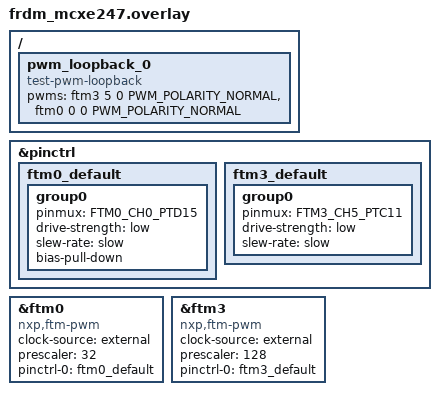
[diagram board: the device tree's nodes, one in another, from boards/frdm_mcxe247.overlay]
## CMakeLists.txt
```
# Copyright 2026 NXP
# SPDX-License-Identifier: Apache-2.0

cmake_minimum_required(VERSION 3.28.0)

# Same test-pwm-loopback binding and wiring as the pwm_loopback test
list(APPEND DTS_ROOT ${CMAKE_CURRENT_SOURCE_DIR}/../pwm_loopback)

find_package(Zephyr REQUIRED HINTS $ENV{ZEPHYR_BASE})
project(pwm_pm)

target_sources(app PRIVATE src/main.c)
target_sources_ifdef(CONFIG_PM_POLICY_DEVICE_CONSTRAINTS app PRIVATE src/policy.c)

# PM_DEVICE_SYSTEM_MANAGED defaults on with PM_DEVICE alone; the sweep only
# exists with system PM.
if(CONFIG_PM AND CONFIG_PM_DEVICE_SYSTEM_MANAGED)
  target_sources(app PRIVATE src/sysmanaged.c)
endif()
```

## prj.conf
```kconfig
CONFIG_ZTEST=y

CONFIG_PWM=y
CONFIG_PWM_CAPTURE=y

CONFIG_PM_DEVICE=y
```

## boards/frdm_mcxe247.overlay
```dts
/*
 * Copyright 2026 NXP
 *
 * SPDX-License-Identifier: Apache-2.0
 */

#include <zephyr/dt-bindings/pwm/pwm.h>

&pinctrl {
	ftm0_default: ftm0_default {
		group0 {
			pinmux = <FTM0_CH0_PTD15>;
			drive-strength = "low";
			slew-rate = "slow";
			/* A suspended FTM leaves its output floating; keep the
			 * line low so a capture on it times out instead of
			 * catching noise.
			 */
			bias-pull-down;
		};
	};

	ftm3_default: ftm3_default {
		group0 {
			pinmux = <FTM3_CH5_PTC11>;
			drive-strength = "low";
			slew-rate = "slow";
		};
	};
};

/* To test this sample, connect
 * PTC11(J1-12) ---> PTD15(J1-14)
 */

/ {
	pwm_loopback_0 {
		compatible = "test-pwm-loopback";
		pwms = <&ftm3 5 0 PWM_POLARITY_NORMAL>, /* PTC11 J1 pin 12 out */
		       <&ftm0 0 0 PWM_POLARITY_NORMAL>; /* PTD15 J1 pin 14 in */
	};
};

&ftm0 {
	compatible = "nxp,ftm-pwm";
	clock-source = "external";
	prescaler = <32>;
	#pwm-cells = <3>;
	pinctrl-0 = <&ftm0_default>;
	pinctrl-names = "default";
	status = "okay";
};

&ftm3 {
	compatible = "nxp,ftm-pwm";
	clock-source = "external";
	prescaler = <128>;
	#pwm-cells = <3>;
	pinctrl-0 = <&ftm3_default>;
	pinctrl-names = "default";
	status = "okay";
};
```

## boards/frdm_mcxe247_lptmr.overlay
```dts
/*
 * Copyright 2026 NXP
 *
 * SPDX-License-Identifier: Apache-2.0
 */

/*
 * With CONFIG_PM=y the SoC enters STOP whenever no lock holds it back, and
 * SysTick does not run there. MCXE24x leaves lptmr0 disabled and not marked
 * as a wake-up source, so enable it as the system timer companion or nothing
 * ends the sleep.
 */
&lptmr0 {
	wakeup-source;
	status = "okay";
};

/ {
	chosen {
		zephyr,system-timer-companion = &lptmr0;
	};
};
```

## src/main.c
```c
/*
 * Copyright 2026 NXP
 *
 * SPDX-License-Identifier: Apache-2.0
 */

#include <zephyr/kernel.h>
#include <zephyr/drivers/pwm.h>
#include <zephyr/pm/device.h>
#include <zephyr/sys/atomic.h>
#include <zephyr/ztest.h>

#include "pwm_pm.h"

/* Ten periods of the 10 ms test waveform */
#define CAPTURE_TIMEOUT K_MSEC(100)
/* Two periods, for a new or replayed setup to reach the pin */
#define SETTLE_TIME K_MSEC(20)

#define REPEAT_COUNT 20

const struct pwm_dt_spec pwm_pm_out = PWM_DT_SPEC_GET_BY_IDX(PWM_PM_NODE, 0);
const struct pwm_dt_spec pwm_pm_in = PWM_DT_SPEC_GET_BY_IDX(PWM_PM_NODE, 1);

static atomic_t capture_count;

static int capture_one(pwm_flags_t type, uint32_t *period, uint32_t *pulse)
{
	return pwm_capture_cycles(pwm_pm_in.dev, pwm_pm_in.channel, pwm_pm_in.flags | type,
				  period, pulse, CAPTURE_TIMEOUT);
}

void pwm_pm_start_output(void)
{
	uint64_t cycles_per_sec;
	uint32_t period;
	int err;

	err = pwm_get_cycles_per_sec(pwm_pm_out.dev, pwm_pm_out.channel, &cycles_per_sec);
	zassert_ok(err, "failed to get the output clock rate (err %d)", err);

	period = cycles_per_sec / 100U;
	err = pwm_set_cycles(pwm_pm_out.dev, pwm_pm_out.channel, period, period / 4U,
			     pwm_pm_out.flags);
	zassert_ok(err, "failed to set pwm output (err %d)", err);

	k_sleep(SETTLE_TIME);
}

void pwm_pm_capture(struct pwm_pm_reading *reading)
{
	uint32_t period;
	uint32_t pulse;
	int err;

	*reading = (struct pwm_pm_reading){0};

	err = capture_one(PWM_CAPTURE_TYPE_PERIOD, &period, &pulse);
	if (err == 0) {
		reading->period = period;
	} else {
		zassert_equal(err, -ENOTSUP, "no period on the line (err %d)", err);
	}

	err = capture_one(PWM_CAPTURE_TYPE_PULSE, &period, &pulse);
	if (err == 0) {
		reading->pulse = pulse;
	} else {
		zassert_equal(err, -ENOTSUP, "no pulse on the line (err %d)", err);
	}

	if (reading->period == 0U && reading->pulse == 0U) {
		TC_PRINT("capture not supported\n");
		ztest_test_skip();
	}
}

void pwm_pm_action(const struct device *dev, enum pm_device_action action)
{
	static const enum pm_device_state target[] = {
		[PM_DEVICE_ACTION_SUSPEND] = PM_DEVICE_STATE_SUSPENDED,
		[PM_DEVICE_ACTION_RESUME] = PM_DEVICE_STATE_ACTIVE,
		[PM_DEVICE_ACTION_TURN_OFF] = PM_DEVICE_STATE_OFF,
		[PM_DEVICE_ACTION_TURN_ON] = PM_DEVICE_STATE_SUSPENDED,
	};
	enum pm_device_state state;
	int err;

	err = pm_device_action_run(dev, action);
	if (action == PM_DEVICE_ACTION_TURN_OFF || action == PM_DEVICE_ACTION_TURN_ON) {
		/* The PM core moves the state on even when the driver does not
		 * handle these, since they report a power change that happened
		 * anyway.
		 */
		zassert_true(err == 0 || err == -ENOTSUP, "%s: action %d failed (err %d)",
			     dev->name, action, err);
	} else {
		zassert_ok(err, "%s: action %d failed (err %d)", dev->name, action, err);
	}

	err = pm_device_state_get(dev, &state);
	zassert_ok(err, "%s: no pm state (err %d)", dev->name, err);
	zassert_equal(state, target[action], "%s is %s after action %d", dev->name,
		      pm_device_state_str(state), action);
}

static void expect_no_output(void)
{
	uint32_t period;
	uint32_t pulse;
	int err;

	err = capture_one(PWM_CAPTURE_TYPE_PERIOD, &period, &pulse);
	if (err == -ENOTSUP) {
		err = capture_one(PWM_CAPTURE_TYPE_PULSE, &period, &pulse);
	}

	zassert_equal(err, -EAGAIN, "output still running while suspended (err %d)", err);
}

static void expect_same(const struct pwm_pm_reading *ref, const struct pwm_pm_reading *now)
{
	zassert_within(now->period, ref->period, MAX(ref->period / 100U, 1U),
		       "period %u, was %u before the transition", now->period, ref->period);
	zassert_within(now->pulse, ref->pulse, MAX(ref->pulse / 100U, 1U),
		       "pulse %u, was %u before the transition", now->pulse, ref->pulse);
}

/*
 * None of the tests below calls pwm_set again after the transition: the
 * driver has to bring back the waveform it was asked for.
 */
ZTEST(pwm_pm, test_suspend_stops_and_resume_restores)
{
	struct pwm_pm_reading ref;
	struct pwm_pm_reading now;

	pwm_pm_start_output();
	pwm_pm_capture(&ref);

	pwm_pm_action(pwm_pm_out.dev, PM_DEVICE_ACTION_SUSPEND);
	expect_no_output();

	pwm_pm_action(pwm_pm_out.dev, PM_DEVICE_ACTION_RESUME);
	k_sleep(SETTLE_TIME);

	pwm_pm_capture(&now);
	expect_same(&ref, &now);
}

ZTEST(pwm_pm, test_power_cycle_restores)
{
	struct pwm_pm_reading ref;
	struct pwm_pm_reading now;

	pwm_pm_start_output();
	pwm_pm_capture(&ref);

	pwm_pm_action(pwm_pm_out.dev, PM_DEVICE_ACTION_SUSPEND);
	pwm_pm_action(pwm_pm_out.dev, PM_DEVICE_ACTION_TURN_OFF);
	pwm_pm_action(pwm_pm_out.dev, PM_DEVICE_ACTION_TURN_ON);
	pwm_pm_action(pwm_pm_out.dev, PM_DEVICE_ACTION_RESUME);
	k_sleep(SETTLE_TIME);

	pwm_pm_capture(&now);
	expect_same(&ref, &now);
}

ZTEST(pwm_pm, test_repeated_suspend_resume)
{
	struct pwm_pm_reading ref;
	struct pwm_pm_reading now;

	pwm_pm_start_output();
	pwm_pm_capture(&ref);

	for (int i = 0; i < REPEAT_COUNT; i++) {
		pwm_pm_action(pwm_pm_out.dev, PM_DEVICE_ACTION_SUSPEND);
		pwm_pm_action(pwm_pm_out.dev, PM_DEVICE_ACTION_RESUME);
	}
	k_sleep(SETTLE_TIME);

	pwm_pm_capture(&now);
	expect_same(&ref, &now);
}

static void count_capture(const struct device *dev, uint32_t channel, uint32_t period_cycles,
			  uint32_t pulse_cycles, int status, void *user_data)
{
	ARG_UNUSED(dev);
	ARG_UNUSED(channel);
	ARG_UNUSED(period_cycles);
	ARG_UNUSED(pulse_cycles);
	ARG_UNUSED(status);
	ARG_UNUSED(user_data);

	atomic_inc(&capture_count);
}

/*
 * A capture does not survive a suspend: the consumer arms it again. What this
 * checks is that the old one is really gone, rather than left armed in
 * hardware to fire into a callback nobody expects, and that a new one works.
 */
ZTEST(pwm_pm, test_capture_device_suspend)
{
	struct pwm_pm_reading ref;
	struct pwm_pm_reading now;
	enum pm_device_state state;
	pwm_flags_t type;
	atomic_val_t seen;
	int err;

	if (pm_device_state_get(pwm_pm_in.dev, &state) == -ENOSYS) {
		TC_PRINT("%s has no device PM\n", pwm_pm_in.dev->name);
		ztest_test_skip();
	}

	if (pwm_pm_in.dev == pwm_pm_out.dev) {
		TC_PRINT("suspending the capture device would stop the output too\n");
		ztest_test_skip();
	}

	pwm_pm_start_output();
	pwm_pm_capture(&ref);

	type = ref.period != 0U ? PWM_CAPTURE_TYPE_PERIOD : PWM_CAPTURE_TYPE_PULSE;
	atomic_clear(&capture_count);

	err = pwm_configure_capture(pwm_pm_in.dev, pwm_pm_in.channel,
				    pwm_pm_in.flags | PWM_CAPTURE_MODE_CONTINUOUS | type,
				    count_capture, NULL);
	zassert_ok(err, "failed to configure pwm capture (err %d)", err);

	err = pwm_enable_capture(pwm_pm_in.dev, pwm_pm_in.channel);
	zassert_ok(err, "failed to enable pwm capture (err %d)", err);

	k_sleep(K_MSEC(50));
	zassert_true(atomic_get(&capture_count) > 0, "continuous capture saw nothing");

	pwm_pm_action(pwm_pm_in.dev, PM_DEVICE_ACTION_SUSPEND);
	pwm_pm_action(pwm_pm_in.dev, PM_DEVICE_ACTION_RESUME);

	seen = atomic_get(&capture_count);
	k_sleep(K_MSEC(50));
	zassert_equal(atomic_get(&capture_count), seen, "capture still running after a suspend");

	pwm_pm_capture(&now);
	expect_same(&ref, &now);
}

bool pwm_pm_supported(const void *global_state)
{
	enum pm_device_state state;

	ARG_UNUSED(global_state);

	if (!pwm_is_ready_dt(&pwm_pm_out) || !pwm_is_ready_dt(&pwm_pm_in)) {
		TC_PRINT("pwm loopback devices are not ready\n");
		return false;
	}

	if (pm_device_state_get(pwm_pm_out.dev, &state) == -ENOSYS) {
		TC_PRINT("%s has no device PM\n", pwm_pm_out.dev->name);
		return false;
	}

	return true;
}

static void resume_if_needed(const struct device *dev)
{
	enum pm_device_state state;

	if (pm_device_state_get(dev, &state) != 0) {
		return;
	}

	if (state == PM_DEVICE_STATE_OFF) {
		(void)pm_device_action_run(dev, PM_DEVICE_ACTION_TURN_ON);
		state = PM_DEVICE_STATE_SUSPENDED;
	}

	if (state == PM_DEVICE_STATE_SUSPENDED) {
		(void)pm_device_action_run(dev, PM_DEVICE_ACTION_RESUME);
	}
}

void pwm_pm_after(void *fixture)
{
	ARG_UNUSED(fixture);

	/* Resume first: a suspended device may not take register access. */
	resume_if_needed(pwm_pm_out.dev);
	resume_if_needed(pwm_pm_in.dev);

	(void)pwm_disable_capture(pwm_pm_in.dev, pwm_pm_in.channel);
}

ZTEST_SUITE(pwm_pm, pwm_pm_supported, NULL, NULL, pwm_pm_after, NULL);
```

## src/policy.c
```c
/*
 * Copyright 2026 NXP
 *
 * SPDX-License-Identifier: Apache-2.0
 */

#include <zephyr/kernel.h>
#include <zephyr/drivers/pwm.h>
#include <zephyr/pm/device.h>
#include <zephyr/pm/policy.h>
#include <zephyr/pm/state.h>
#include <zephyr/ztest.h>

#include "pwm_pm.h"

#if HAS_DISABLING_STATES(PWM_PM_OUT_CTLR)
static const struct pm_state_constraint out_states[] = DISABLING_STATES(PWM_PM_OUT_CTLR);
#endif

#if HAS_DISABLING_STATES(PWM_PM_IN_CTLR)
static const struct pm_state_constraint in_states[] = DISABLING_STATES(PWM_PM_IN_CTLR);
#endif

static __maybe_unused void expect_locked(const struct pm_state_constraint *states,
					 size_t count, bool locked, const char *when)
{
	for (size_t i = 0; i < count; i++) {
		zassert_equal(pm_policy_state_lock_is_active(states[i].state,
							     states[i].substate_id),
			      locked, "state %d/%u %s %s", states[i].state,
			      states[i].substate_id, locked ? "not locked" : "still locked", when);
	}
}

static __maybe_unused void dummy_capture(const struct device *dev, uint32_t channel,
					 uint32_t period_cycles, uint32_t pulse_cycles,
					 int status, void *user_data)
{
	ARG_UNUSED(dev);
	ARG_UNUSED(channel);
	ARG_UNUSED(period_cycles);
	ARG_UNUSED(pulse_cycles);
	ARG_UNUSED(status);
	ARG_UNUSED(user_data);
}

ZTEST(pwm_pm_policy, test_output_holds_power_lock)
{
#if HAS_DISABLING_STATES(PWM_PM_OUT_CTLR)
	pwm_pm_start_output();
	expect_locked(out_states, ARRAY_SIZE(out_states), true, "while driving");

	pwm_pm_action(pwm_pm_out.dev, PM_DEVICE_ACTION_SUSPEND);
	expect_locked(out_states, ARRAY_SIZE(out_states), false, "after suspend");

	/* The replay on resume drives the output again, so the lock comes back. */
	pwm_pm_action(pwm_pm_out.dev, PM_DEVICE_ACTION_RESUME);
	expect_locked(out_states, ARRAY_SIZE(out_states), true, "after resume");
#else
	TC_PRINT("%s declares no disabling power states\n", pwm_pm_out.dev->name);
	ztest_test_skip();
#endif
}

ZTEST(pwm_pm_policy, test_capture_holds_power_lock)
{
#if HAS_DISABLING_STATES(PWM_PM_IN_CTLR)
	pwm_flags_t flags = pwm_pm_in.flags | PWM_CAPTURE_MODE_CONTINUOUS;
	int err;

	/*
	 * Both ends may lock the same states. Suspend the output so that what
	 * is left to hold them is the capture alone.
	 */
	pwm_pm_start_output();
	pwm_pm_action(pwm_pm_out.dev, PM_DEVICE_ACTION_SUSPEND);
	expect_locked(in_states, ARRAY_SIZE(in_states), false, "with nothing running");

	err = pwm_configure_capture(pwm_pm_in.dev, pwm_pm_in.channel,
				    flags | PWM_CAPTURE_TYPE_PERIOD, dummy_capture, NULL);
	if (err == -ENOTSUP) {
		err = pwm_configure_capture(pwm_pm_in.dev, pwm_pm_in.channel,
					    flags | PWM_CAPTURE_TYPE_PULSE, dummy_capture, NULL);
	}
	zassert_ok(err, "failed to configure pwm capture (err %d)", err);

	err = pwm_enable_capture(pwm_pm_in.dev, pwm_pm_in.channel);
	zassert_ok(err, "failed to enable pwm capture (err %d)", err);
	expect_locked(in_states, ARRAY_SIZE(in_states), true, "while capturing");

	err = pwm_disable_capture(pwm_pm_in.dev, pwm_pm_in.channel);
	zassert_ok(err, "failed to disable pwm capture (err %d)", err);
	expect_locked(in_states, ARRAY_SIZE(in_states), false, "after the capture ended");
#else
	TC_PRINT("%s declares no disabling power states\n", pwm_pm_in.dev->name);
	ztest_test_skip();
#endif
}

ZTEST_SUITE(pwm_pm_policy, pwm_pm_supported, NULL, NULL, pwm_pm_after, NULL);
```

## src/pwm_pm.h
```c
/*
 * Copyright 2026 NXP
 *
 * SPDX-License-Identifier: Apache-2.0
 */

#ifndef __TEST_PWM_PM_H__
#define __TEST_PWM_PM_H__

#include <zephyr/kernel.h>
#include <zephyr/drivers/pwm.h>
#include <zephyr/pm/device.h>
#include <zephyr/pm/state.h>
#include <zephyr/ztest.h>

#define PWM_PM_NODE DT_INST(0, test_pwm_loopback)

/* pwms[0] generates the waveform, pwms[1] captures it */
#define PWM_PM_OUT_CTLR DT_PWMS_CTLR_BY_IDX(PWM_PM_NODE, 0)
#define PWM_PM_IN_CTLR  DT_PWMS_CTLR_BY_IDX(PWM_PM_NODE, 1)

/*
 * The states a node lists in zephyr,disabling-power-states are the ones that
 * stop it, and so the ones its driver locks while it is in use.
 */
#define DISABLING_STATE(idx, node_id)                                                    \
	PM_STATE_CONSTRAINT_INIT(DT_PHANDLE_BY_IDX(node_id, zephyr_disabling_power_states, idx))

#define DISABLING_STATES(node_id)                                                        \
	{LISTIFY(DT_PROP_LEN_OR(node_id, zephyr_disabling_power_states, 0), DISABLING_STATE, \
		 (,), node_id)}

#define HAS_DISABLING_STATES(node_id) DT_NODE_HAS_PROP(node_id, zephyr_disabling_power_states)

/* What the capture side read off the line. A field the capture device cannot
 * measure stays at zero and is not compared.
 */
struct pwm_pm_reading {
	uint32_t period;
	uint32_t pulse;
};

extern const struct pwm_dt_spec pwm_pm_out;
extern const struct pwm_dt_spec pwm_pm_in;

/* Start a 10 ms, 25% waveform on the output. */
void pwm_pm_start_output(void);

/* Capture period and pulse; fails the test if the capture side sees nothing. */
void pwm_pm_capture(struct pwm_pm_reading *reading);

/* Run a PM action and check the state it should leave the device in. */
void pwm_pm_action(const struct device *dev, enum pm_device_action action);

/* Suite predicate: both devices ready and the output one has device PM. */
bool pwm_pm_supported(const void *global_state);

/* Suite after hook: bring both devices back to ACTIVE, capture disabled. */
void pwm_pm_after(void *fixture);

#endif /* __TEST_PWM_PM_H__ */
```

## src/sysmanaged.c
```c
/*
 * Copyright 2026 NXP
 *
 * SPDX-License-Identifier: Apache-2.0
 */

#include <zephyr/kernel.h>
#include <zephyr/drivers/pwm.h>
#include <zephyr/pm/device.h>
#include <zephyr/pm/pm.h>
#include <zephyr/sys/atomic.h>
#include <zephyr/ztest.h>

#include "pwm_pm.h"

/* Long enough for the idle thread to pick a power state many times over */
#define IDLE_TIME K_SECONDS(1)

#if HAS_DISABLING_STATES(PWM_PM_OUT_CTLR)
static const struct pm_state_constraint out_states[] = DISABLING_STATES(PWM_PM_OUT_CTLR);

static atomic_t entries;
static atomic_t stopping_entries;
static atomic_t stopping_state;
static atomic_t stopping_substate;

static bool stops_output(enum pm_state state, uint8_t substate_id)
{
	for (size_t i = 0; i < ARRAY_SIZE(out_states); i++) {
		if (out_states[i].state == state && out_states[i].substate_id == substate_id) {
			return true;
		}
	}

	return false;
}

static void state_entry(enum pm_state state, uint8_t substate_id)
{
	atomic_inc(&entries);

	if (stops_output(state, substate_id)) {
		atomic_set(&stopping_state, state);
		atomic_set(&stopping_substate, substate_id);
		atomic_inc(&stopping_entries);
	}
}

static struct pm_notifier notifier = {
	.substate_entry = state_entry,
	.report_substate = true,
};
#endif /* HAS_DISABLING_STATES(PWM_PM_OUT_CTLR) */

/*
 * The system-managed sweep suspends every device that is not busy before a
 * state deeper than runtime-idle, and pays no attention to policy locks. A
 * driving output stays up only because its lock keeps the states that stop it
 * from being picked at all, so that is what this checks: with the output
 * running, the SoC idles, but never into a state the output node lists in
 * zephyr,disabling-power-states. States it does not list are allowed.
 *
 * A capture taken after waking cannot tell: the sweep resumes the device on
 * the way out, the driver replays the waveform, and the gap is gone.
 */
ZTEST(pwm_pm_sysmanaged, test_output_survives_idle)
{
#if HAS_DISABLING_STATES(PWM_PM_OUT_CTLR)
	struct pwm_pm_reading ref;
	struct pwm_pm_reading now;
	enum pm_device_state state;
	int err;

	pwm_pm_start_output();
	pwm_pm_capture(&ref);

	atomic_clear(&entries);
	atomic_clear(&stopping_entries);

	pm_notifier_register(&notifier);
	k_sleep(IDLE_TIME);
	err = pm_notifier_unregister(&notifier);
	zassert_ok(err, "failed to unregister the pm notifier (err %d)", err);

	zassert_equal(atomic_get(&stopping_entries), 0,
		      "SoC entered state %d/%d %d times with the output running",
		      (int)atomic_get(&stopping_state), (int)atomic_get(&stopping_substate),
		      (int)atomic_get(&stopping_entries));
	zassert_true(atomic_get(&entries) > 0, "the SoC never idled");

	err = pm_device_state_get(pwm_pm_out.dev, &state);
	zassert_ok(err, "%s: no pm state (err %d)", pwm_pm_out.dev->name, err);
	zassert_equal(state, PM_DEVICE_STATE_ACTIVE, "%s is %s after idling",
		      pwm_pm_out.dev->name, pm_device_state_str(state));

	pwm_pm_capture(&now);
	zassert_within(now.period, ref.period, MAX(ref.period / 100U, 1U),
		       "period %u, was %u before idling", now.period, ref.period);
	zassert_within(now.pulse, ref.pulse, MAX(ref.pulse / 100U, 1U),
		       "pulse %u, was %u before idling", now.pulse, ref.pulse);
#else
	TC_PRINT("%s declares no disabling power states\n", pwm_pm_out.dev->name);
	ztest_test_skip();
#endif
}

ZTEST_SUITE(pwm_pm_sysmanaged, pwm_pm_supported, NULL, NULL, pwm_pm_after, NULL);
```
